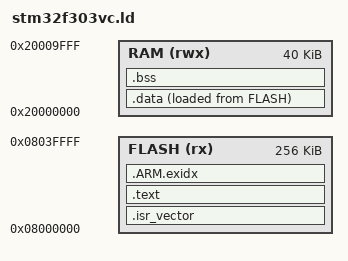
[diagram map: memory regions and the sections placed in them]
/* Linker script for the STM32F303VC (STM32F3DISCOVERY board)
 *   256 KB flash at 0x08000000 (also aliased to 0 for the boot vectors)
 *   40 KB SRAM at 0x20000000  (+8 KB CCM RAM at 0x10000000, unused here)
 */

MEMORY
{
    FLASH (rx)  : ORIGIN = 0x08000000, LENGTH = 256K
    RAM   (rwx) : ORIGIN = 0x20000000, LENGTH = 40K
}

_estack = ORIGIN(RAM) + LENGTH(RAM);

ENTRY(Reset_Handler)

SECTIONS
{
    .isr_vector :
    {
        . = ALIGN(4);
        KEEP(*(.isr_vector))
        . = ALIGN(4);
    } > FLASH

    .text :
    {
        . = ALIGN(4);
        *(.text*)
        *(.rodata*)
        . = ALIGN(4);
        _etext = .;
    } > FLASH

    .ARM.exidx :
    {
        *(.ARM.exidx*)
    } > FLASH

    _sidata = LOADADDR(.data);
    .data :
    {
        . = ALIGN(4);
        _sdata = .;
        *(.data*)
        . = ALIGN(4);
        _edata = .;
    } > RAM AT > FLASH

    .bss :
    {
        . = ALIGN(4);
        _sbss = .;
        *(.bss*)
        *(COMMON)
        . = ALIGN(4);
        _ebss = .;
    } > RAM

    _end = .;
}
